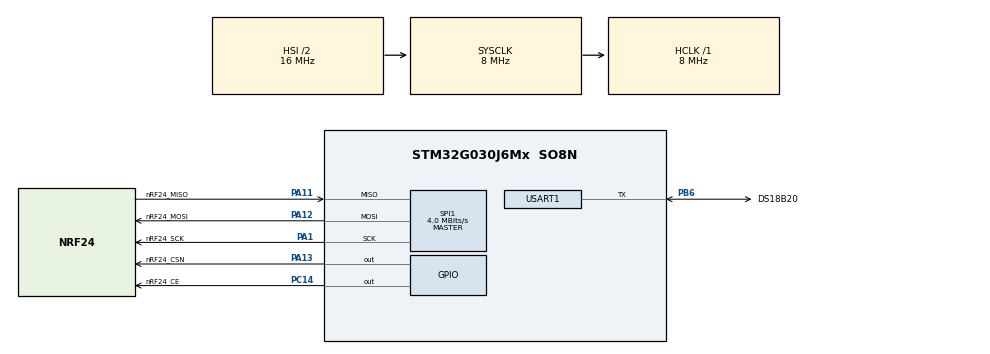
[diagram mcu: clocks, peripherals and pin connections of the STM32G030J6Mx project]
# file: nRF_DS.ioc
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Dma.Request0=USART1_RX
Dma.Request1=USART1_TX
Dma.USART1_RX.0.Direction=DMA_PERIPH_TO_MEMORY
Dma.USART1_RX.0.EventEnable=DISABLE
Dma.USART1_RX.0.Instance=DMA1_Channel1
Dma.USART1_RX.0.MemDataAlignment=DMA_MDATAALIGN_BYTE
Dma.USART1_RX.0.MemInc=DMA_MINC_ENABLE
Dma.USART1_RX.0.Mode=DMA_NORMAL
Dma.USART1_RX.0.PeriphDataAlignment=DMA_PDATAALIGN_BYTE
Dma.USART1_RX.0.PeriphInc=DMA_PINC_DISABLE
Dma.USART1_RX.0.Polarity=HAL_DMAMUX_REQ_GEN_RISING
Dma.USART1_RX.0.Priority=DMA_PRIORITY_LOW
Dma.USART1_RX.0.RequestNumber=1
Dma.USART1_RX.0.SignalID=NONE
Dma.USART1_RX.0.SyncEnable=DISABLE
Dma.USART1_RX.0.SyncPolarity=HAL_DMAMUX_SYNC_NO_EVENT
Dma.USART1_RX.0.SyncRequestNumber=1
Dma.USART1_RX.0.SyncSignalID=NONE
Dma.USART1_TX.1.Direction=DMA_MEMORY_TO_PERIPH
Dma.USART1_TX.1.EventEnable=DISABLE
Dma.USART1_TX.1.Instance=DMA1_Channel2
Dma.USART1_TX.1.MemDataAlignment=DMA_MDATAALIGN_BYTE
Dma.USART1_TX.1.MemInc=DMA_MINC_ENABLE
Dma.USART1_TX.1.Mode=DMA_NORMAL
Dma.USART1_TX.1.PeriphDataAlignment=DMA_PDATAALIGN_BYTE
Dma.USART1_TX.1.PeriphInc=DMA_PINC_DISABLE
Dma.USART1_TX.1.Polarity=HAL_DMAMUX_REQ_GEN_RISING
Dma.USART1_TX.1.Priority=DMA_PRIORITY_LOW
Dma.USART1_TX.1.RequestNumber=1
Dma.USART1_TX.1.SignalID=NONE
Dma.USART1_TX.1.SyncEnable=DISABLE
Dma.USART1_TX.1.SyncPolarity=HAL_DMAMUX_SYNC_NO_EVENT
Dma.USART1_TX.1.SyncRequestNumber=1
Dma.USART1_TX.1.SyncSignalID=NONE
Mcu.Family=STM32G0
Mcu.Name=STM32G030J6Mx
Mcu.Package=SO8N
NVIC.DMA1_Channel1_IRQn=true\:0\:0\:false\:false\:true\:false\:true
NVIC.DMA1_Channel2_3_IRQn=true\:0\:0\:false\:false\:true\:false\:true
NVIC.RTC_TAMP_IRQn=true\:0\:0\:false\:false\:true\:true\:true
NVIC.USART1_IRQn=true\:0\:0\:false\:false\:true\:true\:true
PA1.GPIO_Label=nRF24_SCK
PA1.Mode=Full_Duplex_Master
PA1.Signal=SPI1_SCK
PA11\ [PA9].GPIO_Label=nRF24_MISO
PA11\ [PA9].Mode=Full_Duplex_Master
PA11\ [PA9].Signal=SPI1_MISO
PA12\ [PA10].GPIO_Label=nRF24_MOSI
PA12\ [PA10].Mode=Full_Duplex_Master
PA12\ [PA10].Signal=SPI1_MOSI
PA13.GPIO_Label=nRF24_CSN
PA13.Signal=GPIO_Output
PB6.GPIO_Label=DS18B20
PB6.Mode=Half_duplex(single_wire_mode)
PB6.Signal=USART1_TX
PC14-OSC32_IN\ (PC14).GPIO_Label=nRF24_CE
PC14-OSC32_IN\ (PC14).Signal=GPIO_Output
ProjectManager.HeapSize=0x200
ProjectManager.StackSize=0x400
ProjectManager.TargetToolchain=STM32CubeIDE
RCC.ADCFreq_Value=8000000
RCC.AHBFreq_Value=8000000
RCC.CortexFreq_Value=8000000
RCC.EXTERNAL_CLOCK_VALUE=12288000
RCC.HCLKFreq_Value=8000000
RCC.HSE_VALUE=8000000
RCC.HSISYSCLKDivider=RCC_HSI_DIV2
RCC.HSI_VALUE=16000000
RCC.LSE_VALUE=32768
RCC.SYSCLKFreq_VALUE=8000000
RCC.VCOOutputFreq_Value=128000000
RTC.SynchPrediv=249
RTC.WakeUpClock=RTC_WAKEUPCLOCK_CK_SPRE_16BITS
RTC.WakeUpCounter=59
SPI1.CalculateBaudRate=4.0 MBits/s
SPI1.Direction=SPI_DIRECTION_2LINES
SPI1.Mode=SPI_MODE_MASTER
SPI1.VirtualType=VM_MASTER
USART1.BaudRate=9600
USART1.SwapParam=ADVFEATURE_SWAP_DISABLE
USART1.VirtualMode-Half_duplex(single_wire_mode)=VM_ASYNC
VP_RTC_VS_RTC_Activate.Mode=RTC_Enabled
VP_RTC_VS_RTC_WakeUp_intern.Mode=WakeUp
board=custom

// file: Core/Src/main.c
/* USER CODE BEGIN Header */
/**
  ******************************************************************************
  * @file           : main.c
  * @brief          : Main program body
  ******************************************************************************
  * @attention
  *
  * <h2><center>&copy; Copyright (c) 2020 STMicroelectronics.
  * All rights reserved.</center></h2>
  *
  * This software component is licensed by ST under BSD 3-Clause license,
  * the "License"; You may not use this file except in compliance with the
  * License. You may obtain a copy of the License at:
  *                        opensource.org/licenses/BSD-3-Clause
  *
  ******************************************************************************
  */
/* USER CODE END Header */

#include "main.h"

/* USER CODE BEGIN Includes */
#include "OneWire.h"
#include "nRF24L01.h"
/* USER CODE END Includes */

RTC_HandleTypeDef hrtc;

SPI_HandleTypeDef hspi1;

UART_HandleTypeDef huart1;
DMA_HandleTypeDef hdma_usart1_rx;
DMA_HandleTypeDef hdma_usart1_tx;

void SystemClock_Config(void);
static void MX_GPIO_Init(void);
static void MX_DMA_Init(void);
static void MX_RTC_Init(void);
static void MX_SPI1_Init(void);
static void MX_USART1_UART_Init(void);

int main(void)
{

  /* MCU Configuration--------------------------------------------------------*/

  /* Reset of all peripherals, Initializes the Flash interface and the Systick. */
  HAL_Init();

  /* Configure the system clock */
  SystemClock_Config();

  /* Initialize all configured peripherals */
  MX_GPIO_Init();
  MX_DMA_Init();
  MX_RTC_Init();
  MX_SPI1_Init();
  MX_USART1_UART_Init();
  /* USER CODE BEGIN 2 */
  NRF24_init();

  OW_Init();

  OW_Reset();

  /* USER CODE END 2 */

  /* Infinite loop */
  /* USER CODE BEGIN WHILE */
  while (1)
  {
	  uint16_t *idBase = (uint16_t*)(UID_BASE);
	  //1 wire Temp
	  uint8_t scrach[8]= {0};
	  OW_Send(OW_SEND_RESET, (uint8_t *) "\xCC\x44", 2, (uint8_t *) NULL, 0, OW_NO_READ);// ConvertT

	  HAL_Delay(1000);

	  OW_Send(OW_SEND_RESET, (uint8_t*) "\xCC\xBE\xFF\xFF\xFF\xFF\xFF\xFF\xFF\xFF", 10, scrach, 8, 2);// Get Temp With SkipRom

	  //send from nRF

	  //SLEEEEP
	  HAL_PWR_EnterSTOPMode(PWR_LOWPOWERREGULATOR_ON, PWR_STOPENTRY_WFI);
	  //restart
	  SystemClock_Config();
    /* USER CODE END WHILE */

  }
}

void SystemClock_Config(void)
{
  RCC_OscInitTypeDef RCC_OscInitStruct = {0};
  RCC_ClkInitTypeDef RCC_ClkInitStruct = {0};
  RCC_PeriphCLKInitTypeDef PeriphClkInit = {0};

  /** Configure the main internal regulator output voltage
  */
  HAL_PWREx_ControlVoltageScaling(PWR_REGULATOR_VOLTAGE_SCALE1);
  /** Initializes the CPU, AHB and APB busses clocks
  */
  RCC_OscInitStruct.OscillatorType = RCC_OSCILLATORTYPE_HSI|RCC_OSCILLATORTYPE_LSI;
  RCC_OscInitStruct.HSIState = RCC_HSI_ON;
  RCC_OscInitStruct.HSIDiv = RCC_HSI_DIV2;
  RCC_OscInitStruct.HSICalibrationValue = RCC_HSICALIBRATION_DEFAULT;
  RCC_OscInitStruct.LSIState = RCC_LSI_ON;
  RCC_OscInitStruct.PLL.PLLState = RCC_PLL_NONE;
  if (HAL_RCC_OscConfig(&RCC_OscInitStruct) != HAL_OK)
  {
    Error_Handler();
  }
  /** Initializes the CPU, AHB and APB busses clocks
  */
  RCC_ClkInitStruct.ClockType = RCC_CLOCKTYPE_HCLK|RCC_CLOCKTYPE_SYSCLK
                              |RCC_CLOCKTYPE_PCLK1;
  RCC_ClkInitStruct.SYSCLKSource = RCC_SYSCLKSOURCE_HSI;
  RCC_ClkInitStruct.AHBCLKDivider = RCC_SYSCLK_DIV1;
  RCC_ClkInitStruct.APB1CLKDivider = RCC_HCLK_DIV1;

  if (HAL_RCC_ClockConfig(&RCC_ClkInitStruct, FLASH_LATENCY_0) != HAL_OK)
  {
    Error_Handler();
  }
  /** Initializes the peripherals clocks
  */
  PeriphClkInit.PeriphClockSelection = RCC_PERIPHCLK_RTC|RCC_PERIPHCLK_USART1;
  PeriphClkInit.Usart1ClockSelection = RCC_USART1CLKSOURCE_PCLK1;
  PeriphClkInit.RTCClockSelection = RCC_RTCCLKSOURCE_LSI;

  if (HAL_RCCEx_PeriphCLKConfig(&PeriphClkInit) != HAL_OK)
  {
    Error_Handler();
  }
}

static void MX_RTC_Init(void)
{

  /** Initialize RTC Only
  */
  hrtc.Instance = RTC;
  hrtc.Init.HourFormat = RTC_HOURFORMAT_24;
  hrtc.Init.AsynchPrediv = 127;
  hrtc.Init.SynchPrediv = 249;
  hrtc.Init.OutPut = RTC_OUTPUT_DISABLE;
  hrtc.Init.OutPutRemap = RTC_OUTPUT_REMAP_NONE;
  hrtc.Init.OutPutPolarity = RTC_OUTPUT_POLARITY_HIGH;
  hrtc.Init.OutPutType = RTC_OUTPUT_TYPE_OPENDRAIN;
  hrtc.Init.OutPutPullUp = RTC_OUTPUT_PULLUP_NONE;
  if (HAL_RTC_Init(&hrtc) != HAL_OK)
  {
    Error_Handler();
  }
  /** Enable the WakeUp
  */
  if (HAL_RTCEx_SetWakeUpTimer_IT(&hrtc, 59, RTC_WAKEUPCLOCK_CK_SPRE_16BITS) != HAL_OK)
  {
    Error_Handler();
  }

}

static void MX_SPI1_Init(void)
{

  /* SPI1 parameter configuration*/
  hspi1.Instance = SPI1;
  hspi1.Init.Mode = SPI_MODE_MASTER;
  hspi1.Init.Direction = SPI_DIRECTION_2LINES;
  hspi1.Init.DataSize = SPI_DATASIZE_8BIT;
  hspi1.Init.CLKPolarity = SPI_POLARITY_LOW;
  hspi1.Init.CLKPhase = SPI_PHASE_1EDGE;
  hspi1.Init.NSS = SPI_NSS_SOFT;
  hspi1.Init.BaudRatePrescaler = SPI_BAUDRATEPRESCALER_2;
  hspi1.Init.FirstBit = SPI_FIRSTBIT_MSB;
  hspi1.Init.TIMode = SPI_TIMODE_DISABLE;
  hspi1.Init.CRCCalculation = SPI_CRCCALCULATION_DISABLE;
  hspi1.Init.CRCPolynomial = 7;
  hspi1.Init.CRCLength = SPI_CRC_LENGTH_DATASIZE;
  hspi1.Init.NSSPMode = SPI_NSS_PULSE_ENABLE;
  if (HAL_SPI_Init(&hspi1) != HAL_OK)
  {
    Error_Handler();
  }

}

static void MX_USART1_UART_Init(void)
{

  huart1.Instance = USART1;
  huart1.Init.BaudRate = 9600;
  huart1.Init.WordLength = UART_WORDLENGTH_8B;
  huart1.Init.StopBits = UART_STOPBITS_1;
  huart1.Init.Parity = UART_PARITY_NONE;
  huart1.Init.Mode = UART_MODE_TX_RX;
  huart1.Init.HwFlowCtl = UART_HWCONTROL_NONE;
  huart1.Init.OverSampling = UART_OVERSAMPLING_16;
  huart1.Init.OneBitSampling = UART_ONE_BIT_SAMPLE_DISABLE;
  huart1.Init.ClockPrescaler = UART_PRESCALER_DIV1;
  huart1.AdvancedInit.AdvFeatureInit = UART_ADVFEATURE_NO_INIT;
  if (HAL_HalfDuplex_Init(&huart1) != HAL_OK)
  {
    Error_Handler();
  }
  if (HAL_UARTEx_SetTxFifoThreshold(&huart1, UART_TXFIFO_THRESHOLD_1_8) != HAL_OK)
  {
    Error_Handler();
  }
  if (HAL_UARTEx_SetRxFifoThreshold(&huart1, UART_RXFIFO_THRESHOLD_1_8) != HAL_OK)
  {
    Error_Handler();
  }
  if (HAL_UARTEx_DisableFifoMode(&huart1) != HAL_OK)
  {
    Error_Handler();
  }

}

static void MX_DMA_Init(void)
{

  /* DMA controller clock enable */
  __HAL_RCC_DMA1_CLK_ENABLE();

  /* DMA interrupt init */
  /* DMA1_Channel1_IRQn interrupt configuration */
  HAL_NVIC_SetPriority(DMA1_Channel1_IRQn, 0, 0);
  HAL_NVIC_EnableIRQ(DMA1_Channel1_IRQn);
  /* DMA1_Channel2_3_IRQn interrupt configuration */
  HAL_NVIC_SetPriority(DMA1_Channel2_3_IRQn, 0, 0);
  HAL_NVIC_EnableIRQ(DMA1_Channel2_3_IRQn);

}

static void MX_GPIO_Init(void)
{
  GPIO_InitTypeDef GPIO_InitStruct = {0};

  /* GPIO Ports Clock Enable */
  __HAL_RCC_GPIOC_CLK_ENABLE();
  __HAL_RCC_GPIOA_CLK_ENABLE();
  __HAL_RCC_GPIOB_CLK_ENABLE();

  /*Configure GPIO pin Output Level */
  HAL_GPIO_WritePin(nRF24_CE_GPIO_Port, nRF24_CE_Pin, GPIO_PIN_RESET);

  /*Configure GPIO pin Output Level */
  HAL_GPIO_WritePin(nRF24_CSN_GPIO_Port, nRF24_CSN_Pin, GPIO_PIN_RESET);

  /*Configure GPIO pin : nRF24_CE_Pin */
  GPIO_InitStruct.Pin = nRF24_CE_Pin;
  GPIO_InitStruct.Mode = GPIO_MODE_OUTPUT_PP;
  GPIO_InitStruct.Pull = GPIO_NOPULL;
  GPIO_InitStruct.Speed = GPIO_SPEED_FREQ_LOW;
  HAL_GPIO_Init(nRF24_CE_GPIO_Port, &GPIO_InitStruct);

  /*Configure GPIO pin : nRF24_CSN_Pin */
  GPIO_InitStruct.Pin = nRF24_CSN_Pin;
  GPIO_InitStruct.Mode = GPIO_MODE_OUTPUT_PP;
  GPIO_InitStruct.Pull = GPIO_NOPULL;
  GPIO_InitStruct.Speed = GPIO_SPEED_FREQ_LOW;
  HAL_GPIO_Init(nRF24_CSN_GPIO_Port, &GPIO_InitStruct);

}

void Error_Handler(void)
{
}

/************************ (C) COPYRIGHT STMicroelectronics *****END OF FILE****/
